# S32K322_M7 register map
Vendor: NXP Semiconductors; File version: 1.0
CPU: CM7 r0p1, little endian, MPU, FPU, VTOR, 4 interrupt priority bits
Registers are 32-bit, read-write, reset 0x0 unless marked. A register's access mark holds for its fields unless they carry their own. Offsets are from the block's base; [hi:lo] are bit positions; {n}, {i} and the like mark numbered series; 'fields as' and 'values as' point back to an identical list.

## TCD — DMA TCD
Base 0x40210000
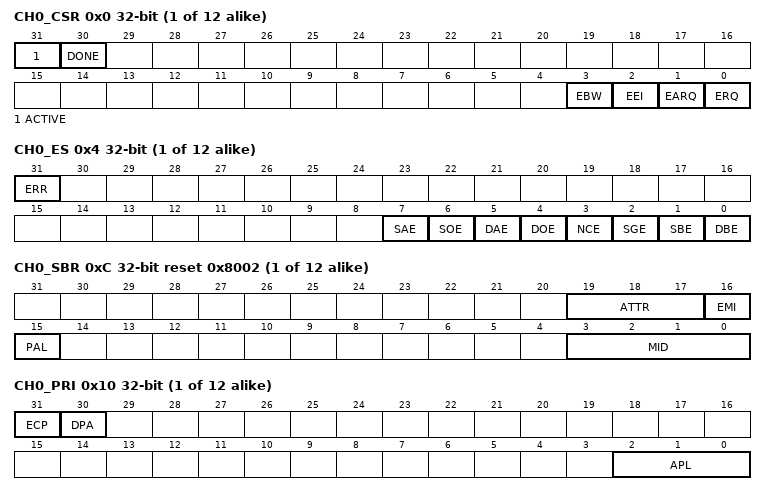
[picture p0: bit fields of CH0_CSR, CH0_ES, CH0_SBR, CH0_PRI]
{0x0+0x4000*i} CH{i}_CSR (i=0..11) — Channel Control and Status
  [31] ACTIVE ro — Channel Active
  [30] DONE write-1-clears — Channel Done
  [3] EBW — Enable Buffered Writes
    0=Buffered writes on system bus disabled; 1=Buffered writes on system bus enabled
  [2] EEI — Enable Error Interrupt
    0=Error signal for corresponding channel does not generate error interrupt; 1=Assertion of error signal for corresponding channel generates error interrupt request
  [1] EARQ — Enable Asynchronous DMA Request In Stop Mode For Channel
    0=Disable asynchronous DMA request for the channel; 1=Enable asynchronous DMA request for the channel
  [0] ERQ — Enable DMA Request
    0=DMA hardware request signal for corresponding channel disabled; 1=DMA hardware request signal for corresponding channel enabled
{0x4+0x4000*i} CH{i}_ES (i=0..11) — Channel Error Status
  [31] ERR write-1-clears — Error In Channel
    0=An error in this channel has not occurred; 1=An error in this channel has occurred
  [7] SAE ro — Source Address Error
    0=No source address configuration error; 1=Last recorded error was a configuration error detected in the TCDn_SADDR field
  [6] SOE ro — Source Offset Error
    0=No source offset configuration error; 1=Last recorded error was a configuration error detected in the TCDn_SOFF field
  [5] DAE ro — Destination Address Error
    0=No destination address configuration error; 1=Last recorded error was a configuration error detected in the TCDn_DADDR field
  [4] DOE ro — Destination Offset Error
    0=No destination offset configuration error; 1=Last recorded error was a configuration error detected in the TCDn_DOFF field
  [3] NCE ro — NBYTES/CITER Configuration Error
    0=No NBYTES/CITER configuration error; 1=Last recorded error was a configuration error detected in the TCDn_NBYTES or TCDn_CITER fields
  [2] SGE ro — Scatter/Gather Configuration Error
    0=No scatter/gather configuration error; 1=Last recorded error was a configuration error detected in the TCDn_DLAST_SGA field
  [1] SBE ro — Source Bus Error
    0=No source bus error; 1=Last recorded error was bus error on source read
  [0] DBE ro — Destination Bus Error
    0=No destination bus error; 1=Last recorded error was bus error on destination write
{0x8+0x4000*i} CH{i}_INT write-1-clears (i=0..11) — Channel Interrupt Status
  [0] INT write-1-clears — Interrupt Request
    0=Interrupt request for corresponding channel cleared; 1=Interrupt request for corresponding channel active
{0xC+0x4000*i} CH{i}_SBR reset 0x8002 (i=0..11) — Channel System Bus
  [19:17] ATTR — Attribute Output
  [16] EMI — Enable Master ID Replication
    0=Master ID replication is disabled; 1=Master ID replication is enabled
  [15] PAL ro — Privileged Access Level
    0=User protection level for DMA transfers; 1=Privileged protection level for DMA transfers
  [3:0] MID ro — Master ID
{0x10+0x4000*i} CH{i}_PRI (i=0..11) — Channel Priority
  [31] ECP — Enable Channel Preemption
    0=Channel cannot be suspended by a higher-priority channel's service request; 1=Channel can be temporarily suspended by a higher-priority channel's service request
  [30] DPA — Disable Preempt Ability
    0=Channel can suspend a lower-priority channel; 1=Channel cannot suspend any other channel, regardless of channel priority
  [2:0] APL — Arbitration Priority Level
{0x20+0x4000*i} TCD{i}_SADDR reset not defined (i=0..11) — TCD Source Address
  [31:0] SADDR — Source Address
{0x24+0x4000*i} TCD{i}_SOFF 16-bit reset not defined (i=0..11) — TCD Signed Source Address Offset
  [15:0] SOFF — Source Address Signed Offset
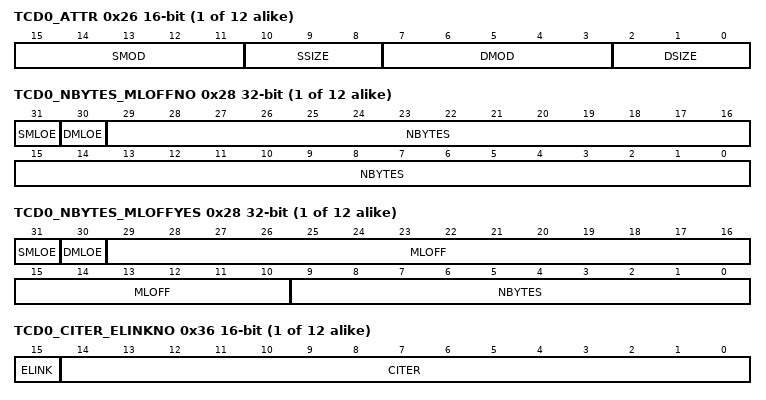
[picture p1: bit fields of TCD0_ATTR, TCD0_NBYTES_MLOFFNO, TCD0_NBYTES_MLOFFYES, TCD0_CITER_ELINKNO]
{0x26+0x4000*i} TCD{i}_ATTR 16-bit reset not defined (i=0..11) — TCD Transfer Attributes
  [15:11] SMOD — Source Address Modulo
    0=Source address modulo feature disabled; 1=Source address modulo feature enabled for any non-zero value [1-31]
  [10:8] SSIZE — Source Data Transfer Size
    0=8-bit; 1=16-bit; 2=32-bit; 3=64-bit; 4=16-byte; 5=32-byte; 6=64-byte
  [7:3] DMOD — Destination Address Modulo
  [2:0] DSIZE — Destination Data Transfer Size
{0x28+0x4000*i} TCD{i}_NBYTES_MLOFFNO reset not defined (NBYTES_index_ view) (i=0..11) — TCD Transfer Size Without Minor Loop Offsets
  [31] SMLOE — Source Minor Loop Offset Enable
    0=Minor loop offset not applied to SADDR; 1=Minor loop offset applied to SADDR
  [30] DMLOE — Destination Minor Loop Offset Enable
    0=Minor loop offset not applied to DADDR; 1=Minor loop offset applied to DADDR
  [29:0] NBYTES — Number of Bytes To Transfer Per Service Request
{0x28+0x4000*i} TCD{i}_NBYTES_MLOFFYES reset not defined (NBYTES_index_ view) (i=0..11) — TCD Transfer Size with Minor Loop Offsets
  [31] SMLOE — Source Minor Loop Offset Enable
    values as TCD0_NBYTES_MLOFFNO.SMLOE
  [30] DMLOE — Destination Minor Loop Offset Enable
    values as TCD0_NBYTES_MLOFFNO.DMLOE
  [29:10] MLOFF — Minor Loop Offset
  [9:0] NBYTES — Number of Bytes To Transfer Per Service Request
{0x2C+0x4000*i} TCD{i}_SLAST_SDA reset not defined (i=0..11) — TCD Last Source Address Adjustment / Store DADDR Address
  [31:0] SLAST_SDA — Last Source Address Adjustment / Store DADDR Address
{0x30+0x4000*i} TCD{i}_DADDR reset not defined (i=0..11) — TCD Destination Address
  [31:0] DADDR — Destination Address
{0x34+0x4000*i} TCD{i}_DOFF 16-bit reset not defined (i=0..11) — TCD Signed Destination Address Offset
  [15:0] DOFF — Destination Address Signed Offset
{0x36+0x4000*i} TCD{i}_CITER_ELINKNO 16-bit reset not defined (CITER_index_ view) (i=0..11) — TCD Current Major Loop Count (Minor Loop Channel Linking Disabled)
  [15] ELINK — Enable Link
    0=Channel-to-channel linking disabled; 1=Channel-to-channel linking enabled
  [14:0] CITER — Current Major Iteration Count
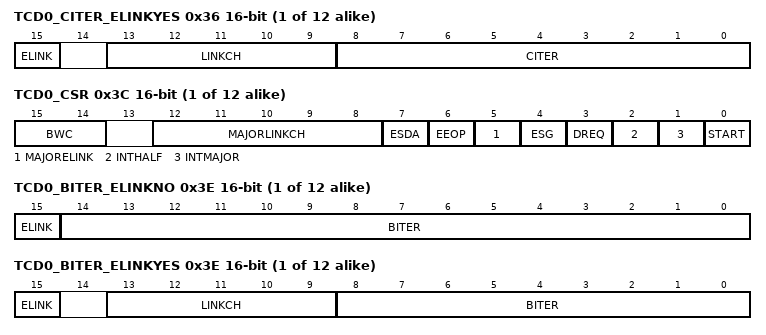
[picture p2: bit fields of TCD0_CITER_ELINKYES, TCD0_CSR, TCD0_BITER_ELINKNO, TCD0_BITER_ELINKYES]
{0x36+0x4000*i} TCD{i}_CITER_ELINKYES 16-bit reset not defined (CITER_index_ view) (i=0..11) — TCD Current Major Loop Count (Minor Loop Channel Linking Enabled)
  [15] ELINK — Enable Link
    values as TCD0_CITER_ELINKNO.ELINK
  [13:9] LINKCH — Minor Loop Link Channel Number
  [8:0] CITER — Current Major Iteration Count
{0x38+0x4000*i} TCD{i}_DLAST_SGA reset not defined (i=0..11) — TCD Last Destination Address Adjustment / Scatter Gather Address
  [31:0] DLAST_SGA — Last Destination Address Adjustment / Scatter Gather Address
{0x3C+0x4000*i} TCD{i}_CSR 16-bit (reset mask 0x1) (i=0..11) — TCD Control and Status
  [15:14] BWC — Bandwidth Control
    0=No eDMA engine stalls; 1=Enable eDMA master high-priority elevation (HPE) mode. No eDMA engine stalls.; 2=eDMA engine stalls for 4 cycles after each R/W; 3=eDMA engine stalls for 8 cycles after each R/W
  [12:8] MAJORLINKCH — Major Loop Link Channel Number
  [7] ESDA — Enable Store Destination Address
    0=Ability to store destination address to system memory disabled; 1=Ability to store destination address to system memory enabled
  [6] EEOP — Enable End-Of-Packet Processing
    0=End-of-packet operation disabled; 1=End-of-packet hardware input signal enabled
  [5] MAJORELINK — Enable Link When Major Loop Complete
    values as TCD0_CITER_ELINKNO.ELINK
  [4] ESG — Enable Scatter/Gather Processing
    0=Current channel's TCD is normal format; 1=Current channel's TCD specifies scatter/gather format
  [3] DREQ — Disable Request
    0=No operation; 1=Clear the ERQ field to 0 upon major loop completion, thus disabling hardware service requests
  [2] INTHALF — Enable Interrupt If Major Counter Half-complete
    0=Halfway point interrupt disabled; 1=Halfway point interrupt enabled
  [1] INTMAJOR — Enable Interrupt If Major count complete
    0=End-of-major loop interrupt disabled; 1=End-of-major loop interrupt enabled
  [0] START — Channel Start
    0=Channel not explicitly started; 1=Channel explicitly started via a software-initiated service request
{0x3E+0x4000*i} TCD{i}_BITER_ELINKNO 16-bit reset not defined (BITER_index_ view) (i=0..11) — TCD Beginning Major Loop Count (Minor Loop Channel Linking Disabled)
  [15] ELINK — Enables Link
    values as TCD0_CITER_ELINKNO.ELINK
  [14:0] BITER — Starting Major Iteration Count
{0x3E+0x4000*i} TCD{i}_BITER_ELINKYES 16-bit reset not defined (BITER_index_ view) (i=0..11) — TCD Beginning Major Loop Count (Minor Loop Channel Linking Enabled)
  [15] ELINK — Enable Link
    values as TCD0_CITER_ELINKNO.ELINK
  [13:9] LINKCH — Link Channel Number
  [8:0] BITER — Starting Major Iteration Count
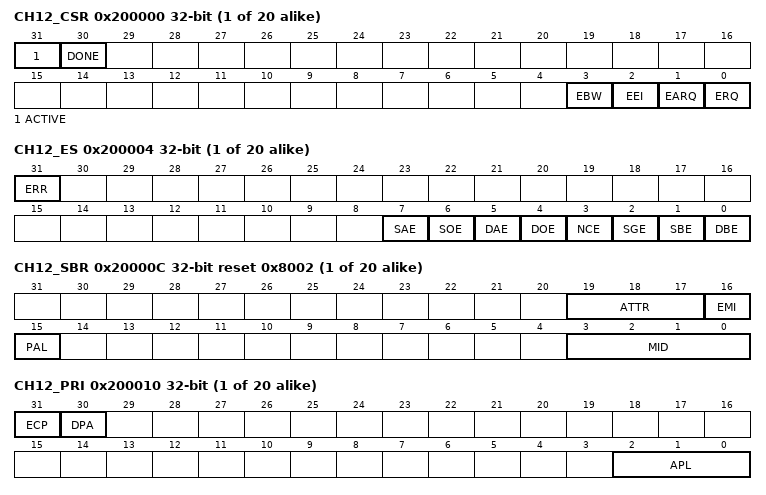
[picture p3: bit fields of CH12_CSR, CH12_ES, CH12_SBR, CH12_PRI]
{0x1D0000+0x4000*i} CH{i}_CSR (i=12..31) — Channel Control and Status
  fields as CH0_CSR
{0x1D0004+0x4000*i} CH{i}_ES (i=12..31) — Channel Error Status
  fields as CH0_ES
{0x1D0008+0x4000*i} CH{i}_INT write-1-clears (i=12..31) — Channel Interrupt Status
  fields as CH0_INT
{0x1D000C+0x4000*i} CH{i}_SBR reset 0x8002 (i=12..31) — Channel System Bus
  fields as CH0_SBR
{0x1D0010+0x4000*i} CH{i}_PRI (i=12..31) — Channel Priority
  fields as CH0_PRI
{0x1D0020+0x4000*i} TCD{i}_SADDR reset not defined (i=12..31) — TCD Source Address
  [31:0] SADDR — Source Address
{0x1D0024+0x4000*i} TCD{i}_SOFF 16-bit reset not defined (i=12..31) — TCD Signed Source Address Offset
  [15:0] SOFF — Source Address Signed Offset
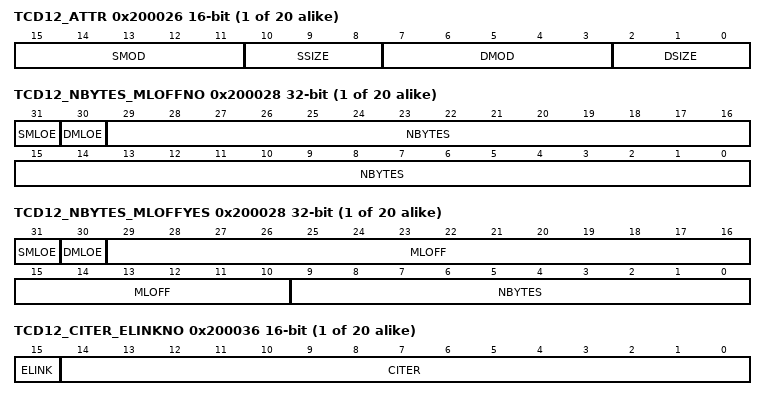
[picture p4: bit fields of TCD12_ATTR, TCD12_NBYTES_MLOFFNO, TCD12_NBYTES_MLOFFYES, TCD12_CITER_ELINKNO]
{0x1D0026+0x4000*i} TCD{i}_ATTR 16-bit reset not defined (i=12..31) — TCD Transfer Attributes
  fields as TCD0_ATTR
{0x1D0028+0x4000*i} TCD{i}_NBYTES_MLOFFNO reset not defined (NBYTES_index_ view) (i=12..31) — TCD Transfer Size Without Minor Loop Offsets
  fields as TCD0_NBYTES_MLOFFNO
{0x1D0028+0x4000*i} TCD{i}_NBYTES_MLOFFYES reset not defined (NBYTES_index_ view) (i=12..31) — TCD Transfer Size with Minor Loop Offsets
  fields as TCD0_NBYTES_MLOFFYES
{0x1D002C+0x4000*i} TCD{i}_SLAST_SDA reset not defined (i=12..31) — TCD Last Source Address Adjustment / Store DADDR Address
  fields as TCD0_SLAST_SDA
{0x1D0030+0x4000*i} TCD{i}_DADDR reset not defined (i=12..31) — TCD Destination Address
  [31:0] DADDR — Destination Address
{0x1D0034+0x4000*i} TCD{i}_DOFF 16-bit reset not defined (i=12..31) — TCD Signed Destination Address Offset
  [15:0] DOFF — Destination Address Signed Offset
{0x1D0036+0x4000*i} TCD{i}_CITER_ELINKNO 16-bit reset not defined (CITER_index_ view) (i=12..31) — TCD Current Major Loop Count (Minor Loop Channel Linking Disabled)
  fields as TCD0_CITER_ELINKNO
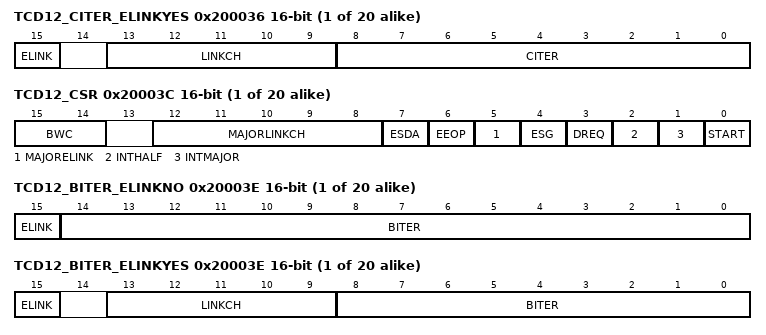
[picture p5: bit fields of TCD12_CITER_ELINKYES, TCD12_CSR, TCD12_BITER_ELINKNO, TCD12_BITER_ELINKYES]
{0x1D0036+0x4000*i} TCD{i}_CITER_ELINKYES 16-bit reset not defined (CITER_index_ view) (i=12..31) — TCD Current Major Loop Count (Minor Loop Channel Linking Enabled)
  fields as TCD0_CITER_ELINKYES
{0x1D0038+0x4000*i} TCD{i}_DLAST_SGA reset not defined (i=12..31) — TCD Last Destination Address Adjustment / Scatter Gather Address
  fields as TCD0_DLAST_SGA
{0x1D003C+0x4000*i} TCD{i}_CSR 16-bit (reset mask 0x1) (i=12..31) — TCD Control and Status
  fields as TCD0_CSR
{0x1D003E+0x4000*i} TCD{i}_BITER_ELINKNO 16-bit reset not defined (BITER_index_ view) (i=12..31) — TCD Beginning Major Loop Count (Minor Loop Channel Linking Disabled)
  fields as TCD0_BITER_ELINKNO
{0x1D003E+0x4000*i} TCD{i}_BITER_ELINKYES 16-bit reset not defined (BITER_index_ view) (i=12..31) — TCD Beginning Major Loop Count (Minor Loop Channel Linking Enabled)
  fields as TCD0_BITER_ELINKYES
